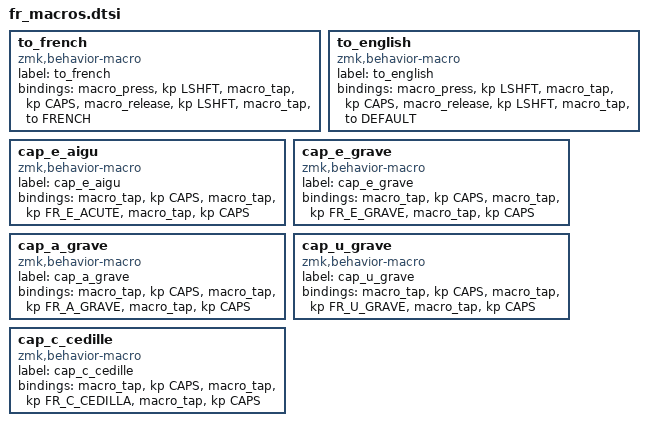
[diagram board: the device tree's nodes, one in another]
to_french: to_french {
	label = "to_french";
            compatible = "zmk,behavior-macro";
            #binding-cells = <0>;
            bindings
                = <&macro_press &kp LSHFT>
                , <&macro_tap &kp CAPS>
                , <&macro_release &kp LSHFT>
                , <&macro_tap &to FRENCH>
                ;
};

to_english: to_english {
	label = "to_english";
            compatible = "zmk,behavior-macro";
            #binding-cells = <0>;
            bindings
                = <&macro_press &kp LSHFT>
                , <&macro_tap &kp CAPS>
                , <&macro_release &kp LSHFT>
                , <&macro_tap &to DEFAULT>
                ;
};

cap_e_aigu: cap_e_aigu {
	label = "cap_e_aigu";
            compatible = "zmk,behavior-macro";
            #binding-cells = <0>;
            bindings
                = <&macro_tap &kp CAPS>
                , <&macro_tap &kp FR_E_ACUTE>
                , <&macro_tap &kp CAPS>
                ;
};

cap_e_grave: cap_e_grave {
	label = "cap_e_grave";
            compatible = "zmk,behavior-macro";
            #binding-cells = <0>;
            bindings
                = <&macro_tap &kp CAPS>
                , <&macro_tap &kp FR_E_GRAVE>
                , <&macro_tap &kp CAPS>
                ;
};

cap_a_grave: cap_a_grave {
	label = "cap_a_grave";
            compatible = "zmk,behavior-macro";
            #binding-cells = <0>;
            bindings
                = <&macro_tap &kp CAPS>
                , <&macro_tap &kp FR_A_GRAVE>
                , <&macro_tap &kp CAPS>
                ;
};

cap_u_grave: cap_u_grave {
	label = "cap_u_grave";
            compatible = "zmk,behavior-macro";
            #binding-cells = <0>;
            bindings
                = <&macro_tap &kp CAPS>
                , <&macro_tap &kp FR_U_GRAVE>
                , <&macro_tap &kp CAPS>
                ;
};

cap_c_cedille: cap_c_cedille {
	label = "cap_c_cedille";
            compatible = "zmk,behavior-macro";
            #binding-cells = <0>;
            bindings
                = <&macro_tap &kp CAPS>
                , <&macro_tap &kp FR_C_CEDILLA>
                , <&macro_tap &kp CAPS>
                ;
};
